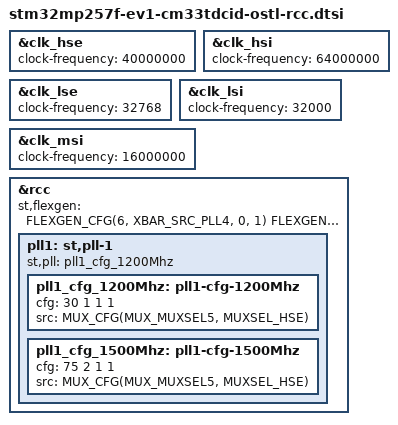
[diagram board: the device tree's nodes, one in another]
// SPDX-License-Identifier: (GPL-2.0-only OR BSD-3-Clause)
/*
 * Copyright (C) STMicroelectronics 2022 - All Rights Reserved
 * Author: Loic Pallardy loic.pallardy@foss.st.com for STMicroelectronics.
 */

/*
 * STM32MP25 Clock tree device tree configuration
 * Project : ostl-beta-m33td
 * Generated by XLmx tool version 2.2 - 11/21/2023 5:45:09 PM
 */

&clk_hse {
	clock-frequency = <40000000>;
};

&clk_hsi {
	clock-frequency = <64000000>;
};

&clk_lse {
	clock-frequency = <32768>;
};

&clk_lsi {
	clock-frequency = <32000>;
};

&clk_msi {
	clock-frequency = <16000000>;
};

&rcc {
	st,flexgen = <
		FLEXGEN_CFG(6, XBAR_SRC_PLL4, 0, 1)
		FLEXGEN_CFG(7, XBAR_SRC_PLL4, 0, 11)
		FLEXGEN_CFG(8, XBAR_SRC_HSI_KER, 0, 0)
		FLEXGEN_CFG(20, XBAR_SRC_HSI_KER, 0, 0)
		FLEXGEN_CFG(26, XBAR_SRC_PLL4, 0, 11)
		/*FLEXGEN_CFG(29, XBAR_SRC_PLL5, 0, 1)*/
		FLEXGEN_CFG(30, XBAR_SRC_HSE_KER, 0, 1)
		/*FLEXGEN_CFG(31, XBAR_SRC_PLL5, 0, 19)*/
		/*FLEXGEN_CFG(32, XBAR_SRC_PLL5, 0, 19)*/
		FLEXGEN_CFG(33, XBAR_SRC_PLL4, 0, 23)
		FLEXGEN_CFG(34, XBAR_SRC_PLL4, 0, 59)
		/*FLEXGEN_CFG(37, XBAR_SRC_PLL5, 0, 3)*/
		/*FLEXGEN_CFG(38, XBAR_SRC_PLL5, 0, 3)*/
		FLEXGEN_CFG(40, XBAR_SRC_LSE, 0, 0)
		FLEXGEN_CFG(41, XBAR_SRC_PLL4, 0, 11)
		FLEXGEN_CFG(45, XBAR_SRC_PLL4, 0, 2)
		/*FLEXGEN_CFG(46, XBAR_SRC_PLL5, 0, 3)*/
		FLEXGEN_CFG(51, XBAR_SRC_PLL4, 0, 5)
		FLEXGEN_CFG(56, XBAR_SRC_PLL4, 0, 5)
		FLEXGEN_CFG(57, XBAR_SRC_HSE_KER, 0, 1)
		FLEXGEN_CFG(58, XBAR_SRC_HSE_KER, 0, 1)
		FLEXGEN_CFG(59, XBAR_SRC_PLL4, 0, 1)
		FLEXGEN_CFG(60, XBAR_SRC_PLL4, 0, 23)
		FLEXGEN_CFG(63, XBAR_SRC_PLL4, 0, 2)
	>;

	pll1: st,pll-1 {
		st,pll = <&pll1_cfg_1200Mhz>;

		pll1_cfg_1200Mhz: pll1-cfg-1200Mhz {
			cfg = <30 1 1 1>;
			src = <MUX_CFG(MUX_MUXSEL5, MUXSEL_HSE)>;
		};

		pll1_cfg_1500Mhz: pll1-cfg-1500Mhz {
			cfg = <75 2 1 1>;
			src = <MUX_CFG(MUX_MUXSEL5, MUXSEL_HSE)>;
		};
	};
};

